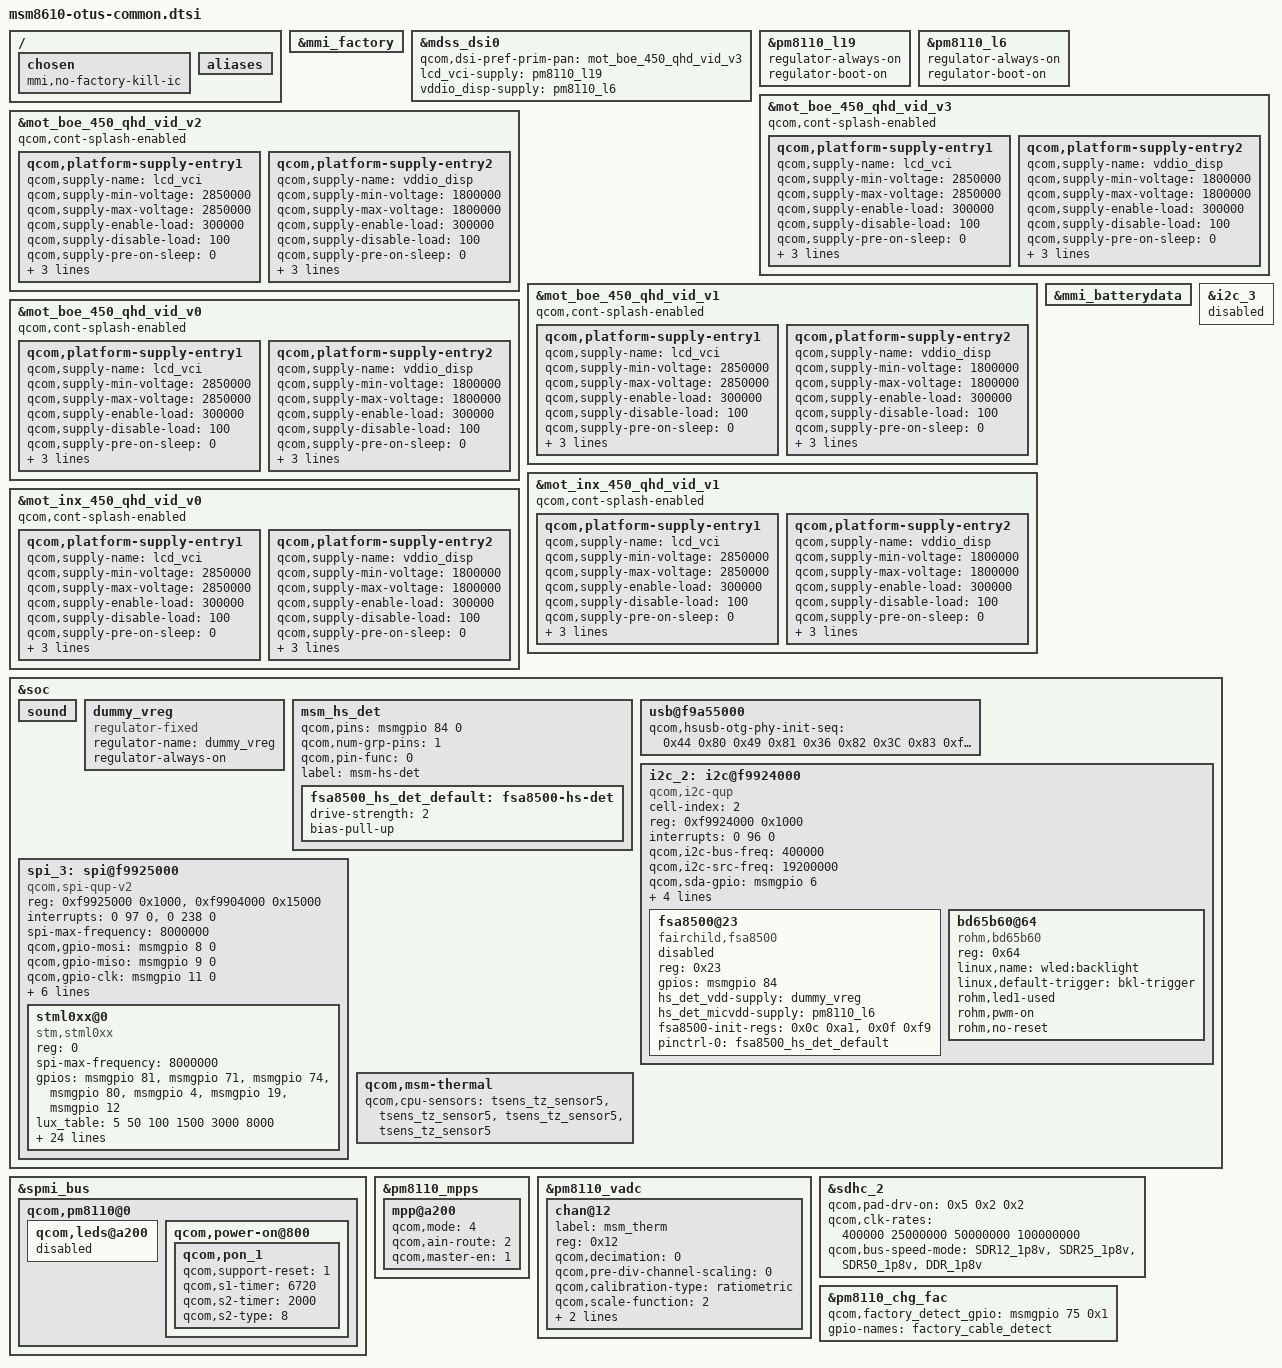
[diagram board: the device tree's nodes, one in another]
/* Copyright (c) 2013, The Linux Foundation. All rights reserved.
 *
 * This program is free software; you can redistribute it and/or modify
 * it under the terms of the GNU General Public License version 2 and
 * only version 2 as published by the Free Software Foundation.
 *
 * This program is distributed in the hope that it will be useful,
 * but WITHOUT ANY WARRANTY; without even the implied warranty of
 * MERCHANTABILITY or FITNESS FOR A PARTICULAR PURPOSE.  See the
 * GNU General Public License for more details.
 */

/include/ "msm8610-moto-reserve.dtsi"
/include/ "msm8610-v1.dtsi"
/include/ "msm8610-camera-sensor-otus-moto.dtsi"
/include/ "msm8610-moto-common.dtsi"
/include/ "msm8610-otus-gpiomux.dtsi"
/include/ "dsi-panel-mot-boe-450-qHD-video.dtsi"
/include/ "dsi-panel-mot-inx-450-qHD-video.dtsi"

/ {
	chosen {
		mmi,no-factory-kill-ic;
	};

	aliases {
		/delete-property/ spi4;
	};
};

&mmi_factory {
	/delete-property/ gpios;
};

&mdss_dsi0 {
	qcom,dsi-pref-prim-pan = <&mot_boe_450_qhd_vid_v3>;
	lcd_vci-supply = <&pm8110_l19>;
	vddio_disp-supply = <&pm8110_l6>;
};

&pm8110_l19 {
	regulator-always-on;
	regulator-boot-on;
};

&pm8110_l6 {
	regulator-always-on;
	regulator-boot-on;
};

&mot_boe_450_qhd_vid_v3 {
	qcom,cont-splash-enabled;
	qcom,platform-supply-entry1 {
		qcom,supply-name = "lcd_vci";
		qcom,supply-min-voltage = <2850000>;
		qcom,supply-max-voltage = <2850000>;
		qcom,supply-enable-load = <300000>;
		qcom,supply-disable-load = <100>;
		qcom,supply-pre-on-sleep = <0>;
		qcom,supply-post-on-sleep = <0>;
		qcom,supply-pre-off-sleep = <0>;
		qcom,supply-post-off-sleep = <0>;
	};
	qcom,platform-supply-entry2 {
		qcom,supply-name = "vddio_disp";
		qcom,supply-min-voltage = <1800000>;
		qcom,supply-max-voltage = <1800000>;
		qcom,supply-enable-load = <300000>;
		qcom,supply-disable-load = <100>;
		qcom,supply-pre-on-sleep = <0>;
		qcom,supply-post-on-sleep = <0>;
		qcom,supply-pre-off-sleep = <0>;
		qcom,supply-post-off-sleep = <0>;
	};
};

&mot_boe_450_qhd_vid_v2 {
	qcom,cont-splash-enabled;
	qcom,platform-supply-entry1 {
		qcom,supply-name = "lcd_vci";
		qcom,supply-min-voltage = <2850000>;
		qcom,supply-max-voltage = <2850000>;
		qcom,supply-enable-load = <300000>;
		qcom,supply-disable-load = <100>;
		qcom,supply-pre-on-sleep = <0>;
		qcom,supply-post-on-sleep = <0>;
		qcom,supply-pre-off-sleep = <0>;
		qcom,supply-post-off-sleep = <0>;
	};
	qcom,platform-supply-entry2 {
		qcom,supply-name = "vddio_disp";
		qcom,supply-min-voltage = <1800000>;
		qcom,supply-max-voltage = <1800000>;
		qcom,supply-enable-load = <300000>;
		qcom,supply-disable-load = <100>;
		qcom,supply-pre-on-sleep = <0>;
		qcom,supply-post-on-sleep = <0>;
		qcom,supply-pre-off-sleep = <0>;
		qcom,supply-post-off-sleep = <0>;
	};
};

&mot_boe_450_qhd_vid_v1 {
	qcom,cont-splash-enabled;
	qcom,platform-supply-entry1 {
		qcom,supply-name = "lcd_vci";
		qcom,supply-min-voltage = <2850000>;
		qcom,supply-max-voltage = <2850000>;
		qcom,supply-enable-load = <300000>;
		qcom,supply-disable-load = <100>;
		qcom,supply-pre-on-sleep = <0>;
		qcom,supply-post-on-sleep = <0>;
		qcom,supply-pre-off-sleep = <0>;
		qcom,supply-post-off-sleep = <0>;
	};
	qcom,platform-supply-entry2 {
		qcom,supply-name = "vddio_disp";
		qcom,supply-min-voltage = <1800000>;
		qcom,supply-max-voltage = <1800000>;
		qcom,supply-enable-load = <300000>;
		qcom,supply-disable-load = <100>;
		qcom,supply-pre-on-sleep = <0>;
		qcom,supply-post-on-sleep = <0>;
		qcom,supply-pre-off-sleep = <0>;
		qcom,supply-post-off-sleep = <0>;
	};
};

&mot_boe_450_qhd_vid_v0 {
	qcom,cont-splash-enabled;
	qcom,platform-supply-entry1 {
		qcom,supply-name = "lcd_vci";
		qcom,supply-min-voltage = <2850000>;
		qcom,supply-max-voltage = <2850000>;
		qcom,supply-enable-load = <300000>;
		qcom,supply-disable-load = <100>;
		qcom,supply-pre-on-sleep = <0>;
		qcom,supply-post-on-sleep = <0>;
		qcom,supply-pre-off-sleep = <0>;
		qcom,supply-post-off-sleep = <0>;
	};
	qcom,platform-supply-entry2 {
		qcom,supply-name = "vddio_disp";
		qcom,supply-min-voltage = <1800000>;
		qcom,supply-max-voltage = <1800000>;
		qcom,supply-enable-load = <300000>;
		qcom,supply-disable-load = <100>;
		qcom,supply-pre-on-sleep = <0>;
		qcom,supply-post-on-sleep = <0>;
		qcom,supply-pre-off-sleep = <0>;
		qcom,supply-post-off-sleep = <0>;
	};
};

&mot_inx_450_qhd_vid_v1 {
	qcom,cont-splash-enabled;
	qcom,platform-supply-entry1 {
		qcom,supply-name = "lcd_vci";
		qcom,supply-min-voltage = <2850000>;
		qcom,supply-max-voltage = <2850000>;
		qcom,supply-enable-load = <300000>;
		qcom,supply-disable-load = <100>;
		qcom,supply-pre-on-sleep = <0>;
		qcom,supply-post-on-sleep = <0>;
		qcom,supply-pre-off-sleep = <0>;
		qcom,supply-post-off-sleep = <0>;
	};
	qcom,platform-supply-entry2 {
		qcom,supply-name = "vddio_disp";
		qcom,supply-min-voltage = <1800000>;
		qcom,supply-max-voltage = <1800000>;
		qcom,supply-enable-load = <300000>;
		qcom,supply-disable-load = <100>;
		qcom,supply-pre-on-sleep = <0>;
		qcom,supply-post-on-sleep = <0>;
		qcom,supply-pre-off-sleep = <0>;
		qcom,supply-post-off-sleep = <0>;
	};
};

&mot_inx_450_qhd_vid_v0 {
	qcom,cont-splash-enabled;
	qcom,platform-supply-entry1 {
		qcom,supply-name = "lcd_vci";
		qcom,supply-min-voltage = <2850000>;
		qcom,supply-max-voltage = <2850000>;
		qcom,supply-enable-load = <300000>;
		qcom,supply-disable-load = <100>;
		qcom,supply-pre-on-sleep = <0>;
		qcom,supply-post-on-sleep = <0>;
		qcom,supply-pre-off-sleep = <0>;
		qcom,supply-post-off-sleep = <0>;
	};
	qcom,platform-supply-entry2 {
		qcom,supply-name = "vddio_disp";
		qcom,supply-min-voltage = <1800000>;
		qcom,supply-max-voltage = <1800000>;
		qcom,supply-enable-load = <300000>;
		qcom,supply-disable-load = <100>;
		qcom,supply-pre-on-sleep = <0>;
		qcom,supply-post-on-sleep = <0>;
		qcom,supply-pre-off-sleep = <0>;
		qcom,supply-post-off-sleep = <0>;
	};
};

&mmi_batterydata {
	/delete-node/ mmi,el40-lishen-batterydata;
	/delete-node/ mmi,el40-sony-batterydata;
	/delete-node/ mmi,el40-atl-batterydata;

	/include/ "batterydata-ft40-lg.dtsi"
	/include/ "batterydata-ft40-sony.dtsi"
	/include/ "batterydata-ft40-lishen.dtsi"
};

&i2c_3 {
	status = "disabled";
};

&soc {
	/delete-node/ fan5646;

	sound {
		/delete-property/ qcom,ext-spk-amp-gpio;
	};

	dummy_vreg: dummy_vreg {
		compatible = "regulator-fixed";
		status = "ok";
		regulator-name = "dummy_vreg";
		regulator-always-on;
	};

	msm_hs_det {
		qcom,pins = <&msmgpio 84 0>;
		qcom,num-grp-pins = <1>;
		qcom,pin-func = <0>;
		label = "msm-hs-det";

		fsa8500_hs_det_default: fsa8500-hs-det {
			drive-strength = <2>;
			bias-pull-up; /* pull up */
		};
	};

	/* Override USB Phy seq for Otus */
	usb@f9a55000 {
		qcom,hsusb-otg-phy-init-seq =
			<0x44 0x80 0x49 0x81 0x36 0x82 0x3C 0x83 0xffffffff>;
	};

	i2c_2: i2c@f9924000 { /* BLSP-1 QUP-2 */
		cell-index = <2>;
		compatible = "qcom,i2c-qup";
		reg = <0xf9924000 0x1000>;
		#address-cells = <1>;
		#size-cells = <0>;
		reg-names = "qup_phys_addr";
		interrupts = <0 96 0>;
		interrupt-names = "qup_err_intr";
		qcom,i2c-bus-freq = <400000>;
		qcom,i2c-src-freq = <19200000>;
		qcom,sda-gpio = <&msmgpio 6 0>;
		qcom,scl-gpio = <&msmgpio 7 0>;
		qcom,noise-rjct-scl = <1>;
		qcom,noise-rjct-sda = <1>;
		qcom,master-id = <86>;

		fsa8500@23 {
			status = "disabled";
			compatible = "fairchild,fsa8500";
			reg = <0x23>;
			gpios = <&msmgpio 84 0x0>;
			hs_det_vdd-supply = <&dummy_vreg>; /* Connected to B-Plus */
			hs_det_micvdd-supply = <&pm8110_l6>;
			fsa8500-init-regs = <0x0c 0xa1>,
					    <0x0f 0xf9>;
			pinctrl-names = "default";
			pinctrl-0 = <&fsa8500_hs_det_default>;
		};

		bd65b60@64 {
			compatible = "rohm,bd65b60";
			reg = <0x64>;
			linux,name = "wled:backlight";
			linux,default-trigger = "bkl-trigger";
			rohm,led1-used;
			rohm,pwm-on;
			rohm,no-reset;
		};
	};
	spi_3: spi@f9925000 { /* BLSP1 QUP3 */
		compatible = "qcom,spi-qup-v2";
		#address-cells = <1>;
		#size-cells = <0>;
		reg-names = "spi_physical", "spi_bam_physical";
		reg = <0xf9925000 0x1000>,
			<0xf9904000 0x15000>;
		interrupt-names = "spi_irq", "spi_bam_irq";
		interrupts = <0 97 0>, <0 238 0>;
		spi-max-frequency = <8000000>;

		qcom,gpio-mosi = <&msmgpio 8 0>;
		qcom,gpio-miso = <&msmgpio 9 0>;
		qcom,gpio-clk  = <&msmgpio 11 0>;
		qcom,gpio-cs0  = <&msmgpio 10 0>;

		qcom,infinite-mode = <0>;
		qcom,ver-reg-exists;
		qcom,bam-consumer-pipe-index = <16>;
		qcom,bam-producer-pipe-index = <17>;
		qcom,master-id = <86>;

		stml0xx@0 {
			compatible = "stm,stml0xx";
			reg = <0>;
			spi-max-frequency = <8000000>;
			gpios = <&msmgpio 81 0>,       /* IRQ */
				<&msmgpio 71 0>,       /* RESET */
				<&msmgpio 74 0>,       /* BSLEN */
				<&msmgpio 80 0>,       /* WakeIRQ */
				<&msmgpio 4 0>,        /* SPI Ready for Receive */
				<&msmgpio 19 0>,       /* SPI Data Ack */
				<&msmgpio 12 0>;       /* Wake Up */
			lux_table = <5 50 100 1500 3000 8000>;
			brightness_table = <9 14 18 46 67 93 140>;
			bslen_pin_active_value = <1>;
			ct406_detect_threshold = <0x00C8>;
			ct406_undetect_threshold = <0x00A5>;
			ct406_recalibrate_threshold = <0x0064>;
			ct406_pulse_count = <0x02>;
			ct406_prox_gain = <0x02>;
			headset_detect_enable = <1>;
			headset_hw_version = <2>;
			headset_insertion_debounce = <0x01F4>;
			headset_removal_debounce = <0x0080>;
			headset_button_down_debounce = <0x0032>;
			headset_button_up_debounce = <0x0032>;
			headset_button_0-1_threshold = <0x009D>;
			headset_button_1-2_threshold = <0x0145>;
			headset_button_2-3_threshold = <0x0201>;
			headset_button_3-upper_threshold = <0x03B0>;
			headset_button_1_keycode = <0xE2>;  /* KEY_MEDIA        */
			headset_button_2_keycode = <0x246>; /* KEY_VOICECOMMAND */
			headset_button_3_keycode = <0x73>;  /* KEY_VOLUMEUP     */
			headset_button_4_keycode = <0x72>;  /* KEY_VOLUMEDOWN   */
			sensor1-supply = <&pm8110_l6>;
			sensor2-supply = <&pm8110_l14>;
			sensor3-supply = <&pm8110_l19>;
		};
	};
	/delete-node/ spi@f9926000;

	qcom,msm-thermal {
		qcom,cpu-sensors = "tsens_tz_sensor5", "tsens_tz_sensor5",
				"tsens_tz_sensor5", "tsens_tz_sensor5";
	};
};

&spmi_bus {
	qcom,pm8110@0 {
		qcom,leds@a200 {
			status = "disabled";
		};

		qcom,power-on@800 {
			qcom,pon_1 {
				qcom,support-reset = <1>;
				qcom,s1-timer = <6720>;
				qcom,s2-timer = <2000>;
				qcom,s2-type = <8>;
			};
		};
	};
};

&pm8110_mpps {
	mpp@a200 { /* MPP 3 */
		qcom,mode = <4>;      /* QPNP_PIN_MODE_AIN */
		qcom,ain-route = <2>; /* QPNP_PIN_AIN_AMUX_CH7 */
		qcom,master-en = <1>; /* Enable MPP */
		status = "ok";
	};
};

&pm8110_vadc {
	chan@12 {
		label = "msm_therm";
		reg = <0x12>;
		qcom,decimation = <0>;
		qcom,pre-div-channel-scaling = <0>;
		qcom,calibration-type = "ratiometric";
		qcom,scale-function = <2>;
		qcom,hw-settle-time = <2>;
		qcom,fast-avg-setup = <0>;
	};
};

&sdhc_2 {
	qcom,pad-drv-on = <0x5 0x2 0x2>; /* 12mA, 6mA, 6mA */
	qcom,clk-rates = <400000 25000000 50000000 100000000>;
	qcom,bus-speed-mode = "SDR12_1p8v", "SDR25_1p8v", "SDR50_1p8v", "DDR_1p8v";
};

&pm8110_chg_fac {
		qcom,factory_detect_gpio = <&msmgpio 75 0x1>; /* GPIOF_DIR_IN | GPIOF_INIT_HIGH */
		gpio-names = "factory_cable_detect";
};
